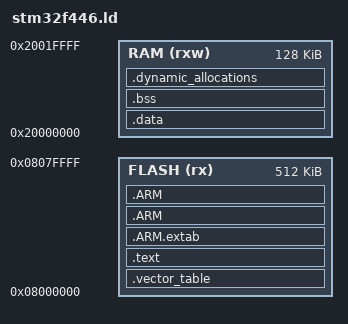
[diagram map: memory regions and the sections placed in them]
ENTRY(Reset_Handler)

_estack = 0x20020000;

MEMORY
{
    FLASH ( rx )      : ORIGIN = 0x08000000, LENGTH = 512K
    RAM ( rxw )       : ORIGIN = 0x20000000, LENGTH = 128K
}

SECTIONS
{
    .vector_table :
    {
        . = ALIGN(4);
        KEEP (*(.vector_table))
        . = ALIGN(4);
    } >FLASH

    .text :
    {
        . = ALIGN(4);
        _text = .;
        *(.text)
        *(.text*)
        *(.rodata)
        *(.rodata*)
        *(.glue_7)
        *(.glue_7t)
        _etext = .;
        . = ALIGN(4);
    } >FLASH

    .ARM.extab : { *(.ARM.extab* .gnu.linkonce.armextab.*) } >FLASH
    .ARM : {
        __exidx_start = .;
        *(.ARM.exidx*)
        __exidx_end = .;
    } >FLASH
    
    _sidata = .;
    .data : AT(_sidata)
    {
        . = ALIGN(4);
        _sdata = .;
        *(.data)
        *(.data*)
        _edata = .;
        . = ALIGN(4);
    } >RAM

    .bss :
    {
        . = ALIGN(4);
        _sbss = .;
        *(.bss)
        *(.bss*)
        *(COMMON)
        . = ALIGN(4);
        _ebss = .;
    } >RAM

    /* Space set aside for the application's heap/stack. */
    .dynamic_allocations :
    {
        . = ALIGN(4);
        _ssystem_ram = .;
        . = ALIGN(4);
        _esystem_ram = .;
    } >RAM

    .ARM : 
    {
        __exidx_start = .;
        *(.ARM.exidx*)
        __exidx_end = .;
    } >FLASH

    /DISCARD/ :
    {
        libc.a ( * )
        libm.a ( * )
        libgcc.a ( * )
    }

    .ARM.attributes 0 : { *(.ARM.attributes) }
}
